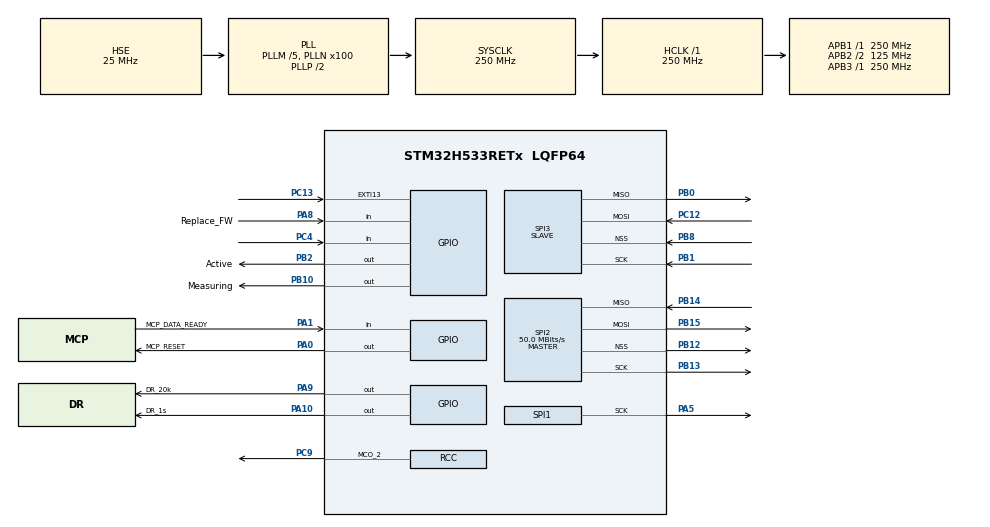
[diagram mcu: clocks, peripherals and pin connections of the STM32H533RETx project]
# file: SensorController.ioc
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BOOTPATH.BootPathName=LEGACY
BOOTPATH.UserSelectedBootPath=LEGACY
CORTEX_M33_NS.userName=CORTEX_M33
Mcu.Family=STM32H5
Mcu.Name=STM32H533RETx
Mcu.Package=LQFP64
NUCLEO-H533RE.BUTTON=1
NUCLEO-H533RE.Bsp_Common_DEMO=true
NUCLEO-H533RE.LD4=true
NUCLEO-H533RE.VCP=true
NVIC.EXTI13_IRQn=true\:0\:0\:false\:false\:true\:false\:true\:true
NVIC.PriorityGroup=NVIC_PRIORITYGROUP_4
PA0.GPIO_Label=MCP_RESET
PA0.GPIO_Speed=GPIO_SPEED_FREQ_HIGH
PA0.PinState=GPIO_PIN_SET
PA0.Signal=GPIO_Output
PA1.GPIO_Label=MCP_DATA_READY
PA1.GPIO_PuPd=GPIO_PULLUP
PA1.Signal=GPIO_Input
PA10.GPIO_Label=DR_1s
PA10.Signal=GPIO_Output
PA13(JTMS/SWDIO).GPIO_Label=SWDIO
PA13(JTMS/SWDIO).Signal=DEBUG_JTMS-SWDIO
PA14(JTCK/SWCLK).GPIO_Label=SWCLK
PA14(JTCK/SWCLK).Signal=DEBUG_JTCK-SWCLK
PA15(JTDI).GPIO_Label=JTDI
PA15(JTDI).Signal=DEBUG_JTDI
PA2.Signal=USART2_TX
PA3.Signal=USART2_RX
PA5.Mode=Full_Duplex_Master
PA5.Signal=SPI1_SCK
PA8.GPIO_Label=Replace_FW
PA8.GPIO_PuPd=GPIO_PULLDOWN
PA8.Signal=GPIO_Input
PA9.GPIO_Label=DR_20k
PA9.Signal=GPIO_Output
PB0.Mode=Full_Duplex_Slave
PB0.Signal=SPI3_MISO
PB1.Mode=Full_Duplex_Slave
PB1.Signal=SPI3_SCK
PB10.GPIO_Label=Measuring
PB10.Signal=GPIO_Output
PB12.Mode=NSS_Signal_Hard_Output
PB12.Signal=SPI2_NSS
PB13.Mode=Full_Duplex_Master
PB13.Signal=SPI2_SCK
PB14.Mode=Full_Duplex_Master
PB14.Signal=SPI2_MISO
PB15.Mode=Full_Duplex_Master
PB15.Signal=SPI2_MOSI
PB2.GPIO_Label=Active
PB2.Signal=GPIO_Output
PB3(JTDO/TRACESWO).GPIO_Label=SWO
PB3(JTDO/TRACESWO).Signal=DEBUG_JTDO-SWO
PB8.Mode=NSS_Signal_Hard_Input
PB8.Signal=SPI3_NSS
PC12.Mode=Full_Duplex_Slave
PC12.Signal=SPI3_MOSI
PC13.Signal=GPXTI13
PC14-OSC32_IN(OSC32_IN).Mode=LSE-External-Oscillator
PC14-OSC32_IN(OSC32_IN).Signal=RCC_OSC32_IN
PC15-OSC32_OUT(OSC32_OUT).Mode=LSE-External-Oscillator
PC15-OSC32_OUT(OSC32_OUT).Signal=RCC_OSC32_OUT
PC4.Signal=GPIO_Input
PC9.Mode=Clock-out-2
PC9.Signal=RCC_MCO_2
PH0-OSC_IN(PH0).Mode=HSE-External-Oscillator
PH0-OSC_IN(PH0).Signal=RCC_OSC_IN
PH1-OSC_OUT(PH1).Mode=HSE-External-Oscillator
PH1-OSC_OUT(PH1).Signal=RCC_OSC_OUT
ProjectManager.HeapSize=0x200
ProjectManager.StackSize=0x400
ProjectManager.TargetToolchain=STM32CubeIDE
RCC.ADCFreq_Value=250000000
RCC.AHBFreq_Value=250000000
RCC.APB1Freq_Value=250000000
RCC.APB1TimFreq_Value=250000000
RCC.APB2CLKDivider=RCC_HCLK_DIV2
RCC.APB2Freq_Value=125000000
RCC.APB2TimFreq_Value=250000000
RCC.APB3Freq_Value=250000000
RCC.CSI_VALUE=4000000
RCC.CortexFreq_Value=250000000
RCC.EPOD_VALUE=25000000
RCC.HCLKFreq_Value=250000000
RCC.HSE_VALUE=25000000
RCC.HSI48_VALUE=48000000
RCC.HSIDiv=RCC_HSI_DIV1
RCC.HSI_VALUE=64000000
RCC.LSIRC_VALUE=32000
RCC.PLL2M=25
RCC.PLL2N=128
RCC.PLL2P=32
RCC.PLL2Source=RCC_PLL2_SOURCE_HSI
RCC.PLL3M=5
RCC.PLL3N=80
RCC.PLL3P=4
RCC.PLL3Source=RCC_PLL3_SOURCE_HSE
RCC.PLLFRACN=0
RCC.PLLM=5
RCC.PLLN=100
RCC.PLLSourceVirtual=RCC_PLL1_SOURCE_HSE
RCC.RCC_MCO2Source=RCC_MCO2SOURCE_PLL2P
RCC.SPI1CLockSelection=RCC_SPI1CLKSOURCE_CLKP
RCC.SPI2CLockSelection=RCC_SPI2CLKSOURCE_PLL3P
RCC.SPI3CLockSelection=RCC_SPI3CLKSOURCE_PLL3P
RCC.SYSCLKFreq_VALUE=250000000
RCC.SYSCLKSource=RCC_SYSCLKSOURCE_PLLCLK
RCC.USBFreq_Value=48000000
RCC.VCOOutputFreq_Value=500000000
SPI2.BaudRatePrescaler=SPI_BAUDRATEPRESCALER_2
SPI2.CalculateBaudRate=50.0 MBits/s
SPI2.Direction=SPI_DIRECTION_2LINES
SPI2.Mode=SPI_MODE_MASTER
SPI2.VirtualNSS=VM_NSSHARD
SPI2.VirtualType=VM_MASTER
SPI3.Direction=SPI_DIRECTION_2LINES
SPI3.Mode=SPI_MODE_SLAVE
SPI3.VirtualNSS=VM_NSSHARD
SPI3.VirtualType=VM_SLAVE
VP_BOOTPATH_VS_BOOTPATH.Mode=BP_Activate
VP_CORTEX_M33_NS_VS_Hclk.Mode=Hclk_Mode
VP_ICACHE_VS_ICACHE.Mode=DirectMappedCache
VP_MEMORYMAP_VS_MEMORYMAP.Mode=CurAppReg
VP_NUCLEO-H533RE_VS_BSP_COMMON.Mode=COMMON
VP_PWR_VS_LPOM.Mode=PowerOptimisation
VP_PWR_VS_SECSignals.Mode=Security/Privilege
VP_RTC_VS_RTC_Activate.Mode=RTC_Enabled
VP_RTC_VS_RTC_Calendar.Mode=RTC_Calendar
VP_TIM6_VS_ClockSourceINT.Mode=Enable_Timer
VP_TIM7_VS_ClockSourceINT.Mode=Enable_Timer
board=NUCLEO-H533RE

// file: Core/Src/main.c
/* USER CODE BEGIN Header */
/**
  ******************************************************************************
  * @file           : main.c
  * @brief          : Main program body
  ******************************************************************************
  * @attention
  *
  * Copyright (c) 2025 STMicroelectronics.
  * All rights reserved.
  *
  * This software is licensed under terms that can be found in the LICENSE file
  * in the root directory of this software component.
  * If no LICENSE file comes with this software, it is provided AS-IS.
  *
  ******************************************************************************
  */
/* USER CODE END Header */
#include "main.h"
#include "icache.h"
#include "rtc.h"
#include "spi.h"
#include "tim.h"
#include "gpio.h"

/* USER CODE BEGIN Includes */
/*This is a test if the version control works : TEST 02*/

/* USER CODE END Includes */

COM_InitTypeDef BspCOMInit;
__IO uint32_t BspButtonState = BUTTON_RELEASED;

void SystemClock_Config(void);
void PeriphCommonClock_Config(void);

int main(void)
{

  /* MCU Configuration--------------------------------------------------------*/

  /* Reset of all peripherals, Initializes the Flash interface and the Systick. */
  HAL_Init();

  /* Configure the system clock */
  SystemClock_Config();

  /* Configure the peripherals common clocks */
  PeriphCommonClock_Config();

  /* Initialize all configured peripherals */
  MX_GPIO_Init();
  MX_SPI2_Init();
  MX_SPI3_Init();
  MX_RTC_Init();
  MX_TIM6_Init();
  MX_TIM7_Init();
  MX_ICACHE_Init();

  /* Initialize leds */
  BSP_LED_Init(LED_GREEN);

  /* Initialize USER push-button, will be used to trigger an interrupt each time it's pressed.*/
  BSP_PB_Init(BUTTON_USER, BUTTON_MODE_EXTI);

  /* Initialize COM1 port (115200, 8 bits (7-bit data + 1 stop bit), no parity */
  BspCOMInit.BaudRate   = 115200;
  BspCOMInit.WordLength = COM_WORDLENGTH_8B;
  BspCOMInit.StopBits   = COM_STOPBITS_1;
  BspCOMInit.Parity     = COM_PARITY_NONE;
  BspCOMInit.HwFlowCtl  = COM_HWCONTROL_NONE;
  if (BSP_COM_Init(COM1, &BspCOMInit) != BSP_ERROR_NONE)
  {
    Error_Handler();
  }

  /* USER CODE BEGIN BSP */

  /* -- Sample board code to send message over COM1 port ---- */
  printf("Welcome to STM32 world !\n\r");

  /* -- Sample board code to switch on leds ---- */
  BSP_LED_On(LED_GREEN);

  /* USER CODE END BSP */

  /* Infinite loop */
  /* USER CODE BEGIN WHILE */
  while (1)
  {

    /* -- Sample board code for User push-button in interrupt mode ---- */
    if (BspButtonState == BUTTON_PRESSED)
    {
      /* Update button state */
      BspButtonState = BUTTON_RELEASED;
      /* -- Sample board code to toggle leds ---- */
      BSP_LED_Toggle(LED_GREEN);
      /* ..... Perform your action ..... */
    }

    /* USER CODE END WHILE */

  }
}

void SystemClock_Config(void)
{
  RCC_OscInitTypeDef RCC_OscInitStruct = {0};
  RCC_ClkInitTypeDef RCC_ClkInitStruct = {0};

  /** Configure the main internal regulator output voltage
  */
  __HAL_PWR_VOLTAGESCALING_CONFIG(PWR_REGULATOR_VOLTAGE_SCALE0);

  while(!__HAL_PWR_GET_FLAG(PWR_FLAG_VOSRDY)) {}

  /** Initializes the RCC Oscillators according to the specified parameters
  * in the RCC_OscInitTypeDef structure.
  */
  RCC_OscInitStruct.OscillatorType = RCC_OSCILLATORTYPE_LSI|RCC_OSCILLATORTYPE_HSE;
  RCC_OscInitStruct.HSEState = RCC_HSE_ON;
  RCC_OscInitStruct.LSIState = RCC_LSI_ON;
  RCC_OscInitStruct.PLL.PLLState = RCC_PLL_ON;
  RCC_OscInitStruct.PLL.PLLSource = RCC_PLL1_SOURCE_HSE;
  RCC_OscInitStruct.PLL.PLLM = 5;
  RCC_OscInitStruct.PLL.PLLN = 100;
  RCC_OscInitStruct.PLL.PLLP = 2;
  RCC_OscInitStruct.PLL.PLLQ = 2;
  RCC_OscInitStruct.PLL.PLLR = 2;
  RCC_OscInitStruct.PLL.PLLRGE = RCC_PLL1_VCIRANGE_2;
  RCC_OscInitStruct.PLL.PLLVCOSEL = RCC_PLL1_VCORANGE_WIDE;
  RCC_OscInitStruct.PLL.PLLFRACN = 0;
  if (HAL_RCC_OscConfig(&RCC_OscInitStruct) != HAL_OK)
  {
    Error_Handler();
  }

  /** Initializes the CPU, AHB and APB buses clocks
  */
  RCC_ClkInitStruct.ClockType = RCC_CLOCKTYPE_HCLK|RCC_CLOCKTYPE_SYSCLK
                              |RCC_CLOCKTYPE_PCLK1|RCC_CLOCKTYPE_PCLK2
                              |RCC_CLOCKTYPE_PCLK3;
  RCC_ClkInitStruct.SYSCLKSource = RCC_SYSCLKSOURCE_PLLCLK;
  RCC_ClkInitStruct.AHBCLKDivider = RCC_SYSCLK_DIV1;
  RCC_ClkInitStruct.APB1CLKDivider = RCC_HCLK_DIV1;
  RCC_ClkInitStruct.APB2CLKDivider = RCC_HCLK_DIV2;
  RCC_ClkInitStruct.APB3CLKDivider = RCC_HCLK_DIV1;

  if (HAL_RCC_ClockConfig(&RCC_ClkInitStruct, FLASH_LATENCY_5) != HAL_OK)
  {
    Error_Handler();
  }
  __HAL_RCC_PLL2_CLKOUT_ENABLE(RCC_PLL2_DIVP);
  HAL_RCC_MCOConfig(RCC_MCO2, RCC_MCO2SOURCE_PLL2P, RCC_MCODIV_1);

  /** Configure the programming delay
  */
  __HAL_FLASH_SET_PROGRAM_DELAY(FLASH_PROGRAMMING_DELAY_2);
}

void PeriphCommonClock_Config(void)
{
  RCC_PeriphCLKInitTypeDef PeriphClkInitStruct = {0};

  /** Initializes the peripherals clock
  */
  PeriphClkInitStruct.PeriphClockSelection = RCC_PERIPHCLK_SPI2|RCC_PERIPHCLK_SPI3;
  PeriphClkInitStruct.PLL3.PLL3Source = RCC_PLL3_SOURCE_HSE;
  PeriphClkInitStruct.PLL3.PLL3M = 5;
  PeriphClkInitStruct.PLL3.PLL3N = 80;
  PeriphClkInitStruct.PLL3.PLL3P = 4;
  PeriphClkInitStruct.PLL3.PLL3Q = 2;
  PeriphClkInitStruct.PLL3.PLL3R = 2;
  PeriphClkInitStruct.PLL3.PLL3RGE = RCC_PLL3_VCIRANGE_0;
  PeriphClkInitStruct.PLL3.PLL3VCOSEL = RCC_PLL3_VCORANGE_MEDIUM;
  PeriphClkInitStruct.PLL3.PLL3FRACN = 0;
  PeriphClkInitStruct.PLL3.PLL3ClockOut = RCC_PLL3_DIVP;
  PeriphClkInitStruct.Spi2ClockSelection = RCC_SPI2CLKSOURCE_PLL3P;
  PeriphClkInitStruct.Spi3ClockSelection = RCC_SPI3CLKSOURCE_PLL3P;
  if (HAL_RCCEx_PeriphCLKConfig(&PeriphClkInitStruct) != HAL_OK)
  {
    Error_Handler();
  }
}

/**
  * @brief  BSP Push Button callback
  * @param  Button Specifies the pressed button
  * @retval None
  */
void BSP_PB_Callback(Button_TypeDef Button)
{
  if (Button == BUTTON_USER)
  {
    BspButtonState = BUTTON_PRESSED;
  }
}

void Error_Handler(void)
{
  __disable_irq();
  while (1)
  {
  }
}
